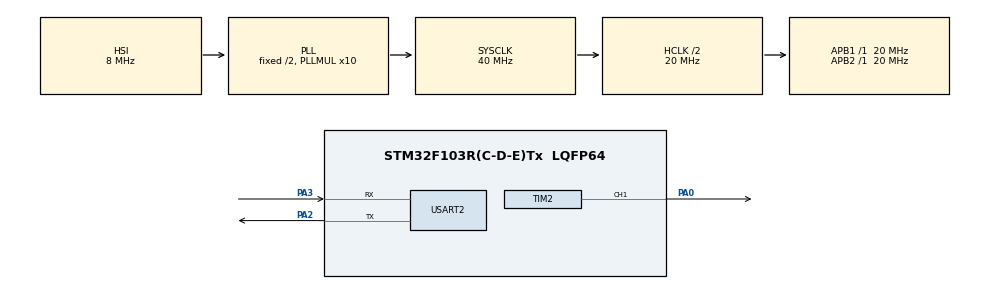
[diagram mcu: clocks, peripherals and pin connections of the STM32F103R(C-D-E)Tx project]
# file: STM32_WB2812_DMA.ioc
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Dma.Request0=TIM2_CH1
Dma.Request1=USART2_RX
Dma.Request2=USART2_TX
Dma.TIM2_CH1.0.Direction=DMA_MEMORY_TO_PERIPH
Dma.TIM2_CH1.0.Instance=DMA1_Channel5
Dma.TIM2_CH1.0.MemDataAlignment=DMA_MDATAALIGN_BYTE
Dma.TIM2_CH1.0.MemInc=DMA_MINC_ENABLE
Dma.TIM2_CH1.0.Mode=DMA_NORMAL
Dma.TIM2_CH1.0.PeriphDataAlignment=DMA_PDATAALIGN_HALFWORD
Dma.TIM2_CH1.0.PeriphInc=DMA_PINC_DISABLE
Dma.TIM2_CH1.0.Priority=DMA_PRIORITY_HIGH
Dma.USART2_RX.1.Direction=DMA_PERIPH_TO_MEMORY
Dma.USART2_RX.1.Instance=DMA1_Channel6
Dma.USART2_RX.1.MemDataAlignment=DMA_MDATAALIGN_BYTE
Dma.USART2_RX.1.MemInc=DMA_MINC_ENABLE
Dma.USART2_RX.1.Mode=DMA_NORMAL
Dma.USART2_RX.1.PeriphDataAlignment=DMA_PDATAALIGN_BYTE
Dma.USART2_RX.1.PeriphInc=DMA_PINC_DISABLE
Dma.USART2_RX.1.Priority=DMA_PRIORITY_LOW
Dma.USART2_TX.2.Direction=DMA_MEMORY_TO_PERIPH
Dma.USART2_TX.2.Instance=DMA1_Channel7
Dma.USART2_TX.2.MemDataAlignment=DMA_MDATAALIGN_BYTE
Dma.USART2_TX.2.MemInc=DMA_MINC_ENABLE
Dma.USART2_TX.2.Mode=DMA_NORMAL
Dma.USART2_TX.2.PeriphDataAlignment=DMA_PDATAALIGN_BYTE
Dma.USART2_TX.2.PeriphInc=DMA_PINC_DISABLE
Dma.USART2_TX.2.Priority=DMA_PRIORITY_LOW
FREERTOS.Tasks01=Wb2812TranferTa,8,128,Wb2812TranferCallback,Default,NULL,Dynamic,NULL,NULL;UartReceiveTask,24,128,UartReceiveCallback,Default,NULL,Dynamic,NULL,NULL;UartSendTask,40,128,UartSendCallback,Default,NULL,Dynamic,NULL,NULL;UartHandleTask,16,128,UartHandleCallback,Default,NULL,Dynamic,NULL,NULL
Mcu.Family=STM32F1
Mcu.Name=STM32F103R(C-D-E)Tx
Mcu.Package=LQFP64
NVIC.DMA1_Channel5_IRQn=true\:5\:0\:false\:false\:true\:true\:false\:true\:true
NVIC.DMA1_Channel6_IRQn=true\:5\:0\:false\:false\:true\:true\:false\:true\:true
NVIC.DMA1_Channel7_IRQn=true\:5\:0\:false\:false\:true\:true\:false\:true\:true
NVIC.PriorityGroup=NVIC_PRIORITYGROUP_4
NVIC.TIM2_IRQn=true\:5\:0\:false\:false\:true\:true\:true\:true\:true
NVIC.USART2_IRQn=true\:5\:0\:false\:false\:true\:true\:true\:true\:true
PA0-WKUP.Signal=S_TIM2_CH1_ETR
PA13.Mode=Serial_Wire
PA13.Signal=SYS_JTMS-SWDIO
PA14.Mode=Serial_Wire
PA14.Signal=SYS_JTCK-SWCLK
PA2.Mode=Asynchronous
PA2.Signal=USART2_TX
PA3.Mode=Asynchronous
PA3.Signal=USART2_RX
PD0-OSC_IN.Mode=HSE-External-Oscillator
PD0-OSC_IN.Signal=RCC_OSC_IN
PD1-OSC_OUT.Mode=HSE-External-Oscillator
PD1-OSC_OUT.Signal=RCC_OSC_OUT
ProjectManager.HeapSize=0x200
ProjectManager.StackSize=0x400
ProjectManager.TargetToolchain=STM32CubeIDE
RCC.AHBCLKDivider=RCC_SYSCLK_DIV2
RCC.AHBFreq_Value=20000000
RCC.APB1Freq_Value=20000000
RCC.APB1TimFreq_Value=20000000
RCC.APB2Freq_Value=20000000
RCC.APB2TimFreq_Value=20000000
RCC.HCLKFreq_Value=20000000
RCC.HSE_VALUE=12000000
RCC.PLLMUL=RCC_PLL_MUL10
RCC.SYSCLKFreq_VALUE=40000000
RCC.SYSCLKSource=RCC_SYSCLKSOURCE_PLLCLK
RCC.USBFreq_Value=26666666.666666668
RCC.USBPrescaler=RCC_USBCLKSOURCE_PLL_DIV1_5
SH.S_TIM2_CH1_ETR.0=TIM2_CH1,PWM Generation1 CH1
TIM2.AutoReloadPreload=TIM_AUTORELOAD_PRELOAD_ENABLE
TIM2.Channel-PWM\ Generation1\ CH1=TIM_CHANNEL_1
TIM2.Period=12
TIM2.Prescaler=1
TIM2.Pulse-PWM\ Generation1\ CH1=0
USART2.VirtualMode=VM_ASYNC
VP_FREERTOS_VS_CMSIS_V2.Mode=CMSIS_V2
VP_TIM2_VS_ClockSourceINT.Mode=Internal
board=custom

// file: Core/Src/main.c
/* USER CODE BEGIN Header */
/**
 ******************************************************************************
 * @file           : main.c
 * @brief          : Main program body
 ******************************************************************************
 * @attention
 *
 * Copyright (c) 2026 STMicroelectronics.
 * All rights reserved.
 *
 * This software is licensed under terms that can be found in the LICENSE file
 * in the root directory of this software component.
 * If no LICENSE file comes with this software, it is provided AS-IS.
 *
 ******************************************************************************
 */
/* USER CODE END Header */
#include "main.h"
#include "cmsis_os.h"

/* USER CODE BEGIN Includes */
#include "WB2812.h"
#include "UartCustom.h"
#include "message.h"
/* USER CODE END Includes */

/* USER CODE BEGIN PTD */
typedef enum{
	UART_CODE_NOT_USED														= 0x11,
	UART_CODE_HEADER														= 0x89,
	UART_CODE_GET_PIXEL_LED													= 0x100,
	UART_CODE_SET_COLOR														= 0x999,
	UART_CODE_SET_COLOR_OK													= 0x1001
} opCodeUartEnum;

/* USER CODE END PTD */

/* USER CODE BEGIN PD */
#define WB2812_CODE_0_DUTY														4
#define WB2812_CODE_1_DUTY														8
#define WB2812_WIDTH															2
#define WB2812_HEIGTH															1
#define WB2812_TIME_DUTY_CODE_0													4
#define WB2812_TIME_DUTY_CODE_1													7
#define WB2812_RED_BALANCE														1
#define WB2812_GREEN_BALANCE													1
#define WB2812_BLUE_BALANCE														1
#define WB2812_GAMMA															2.4
#define MSG_LENGTH_MAX															128
#define QUEUE_SIZE_MAX															3
/* USER CODE END PD */

TIM_HandleTypeDef htim2;
DMA_HandleTypeDef hdma_tim2_ch1;

UART_HandleTypeDef huart2;
DMA_HandleTypeDef hdma_usart2_rx;
DMA_HandleTypeDef hdma_usart2_tx;

/* Definitions for Wb2812TranferTa */
osThreadId_t Wb2812TranferTaHandle;
const osThreadAttr_t Wb2812TranferTa_attributes = {
  .name = "Wb2812TranferTa",
  .stack_size = 128 * 4,
  .priority = (osPriority_t) osPriorityLow,
};
/* Definitions for UartReceiveTask */
osThreadId_t UartReceiveTaskHandle;
const osThreadAttr_t UartReceiveTask_attributes = {
  .name = "UartReceiveTask",
  .stack_size = 128 * 4,
  .priority = (osPriority_t) osPriorityNormal,
};
/* Definitions for UartSendTask */
osThreadId_t UartSendTaskHandle;
const osThreadAttr_t UartSendTask_attributes = {
  .name = "UartSendTask",
  .stack_size = 128 * 4,
  .priority = (osPriority_t) osPriorityHigh,
};
/* Definitions for UartHandleTask */
osThreadId_t UartHandleTaskHandle;
const osThreadAttr_t UartHandleTask_attributes = {
  .name = "UartHandleTask",
  .stack_size = 128 * 4,
  .priority = (osPriority_t) osPriorityBelowNormal,
};
/* USER CODE BEGIN PV */
MsgQueue uartMsgQueueReceive;
MsgQueue uartMsgQueueSend;
WB2812Image_t image;
TaskHandle_t wb2812Task;
TaskHandle_t wb2812requestTask;
/* USER CODE END PV */

void SystemClock_Config(void);
static void MX_GPIO_Init(void);
static void MX_DMA_Init(void);
static void MX_TIM2_Init(void);
static void MX_USART2_UART_Init(void);
void Wb2812TranferCallback(void *argument);
void UartReceiveCallback(void *argument);
void UartSendCallback(void *argument);
void UartHandleCallback(void *argument);

/* USER CODE BEGIN PFP */
static void WB2812Config(void);
void HandleMsgUart(uint8_t *content);
void CopyWb2812ImageByte(uint8_t *content, uint32_t size, Msg *msg);
/* USER CODE END PFP */

int main(void)
{

  /* MCU Configuration--------------------------------------------------------*/

  /* Reset of all peripherals, Initializes the Flash interface and the Systick. */
  HAL_Init();

  /* Configure the system clock */
  SystemClock_Config();

  /* Initialize all configured peripherals */
  MX_GPIO_Init();
  MX_DMA_Init();
  MX_TIM2_Init();
  MX_USART2_UART_Init();
  /* USER CODE BEGIN 2 */
	UartCustomInit(&huart2, MSG_LENGTH_MAX);
	WB2812Config();
	WB2812ImageInit(&image);
  /* USER CODE END 2 */

  /* Init scheduler */
  osKernelInitialize();

  /* USER CODE BEGIN RTOS_QUEUES */
	/* add queues, ... */
	MsgQueueInit(&uartMsgQueueReceive, QUEUE_SIZE_MAX, MSG_LENGTH_MAX);
	MsgQueueInit(&uartMsgQueueSend, QUEUE_SIZE_MAX, MSG_LENGTH_MAX);
  /* USER CODE END RTOS_QUEUES */

  /* Create the thread(s) */
  /* creation of Wb2812TranferTa */
  Wb2812TranferTaHandle = osThreadNew(Wb2812TranferCallback, NULL, &Wb2812TranferTa_attributes);

  /* creation of UartReceiveTask */
  UartReceiveTaskHandle = osThreadNew(UartReceiveCallback, NULL, &UartReceiveTask_attributes);

  /* creation of UartSendTask */
  UartSendTaskHandle = osThreadNew(UartSendCallback, NULL, &UartSendTask_attributes);

  /* creation of UartHandleTask */
  UartHandleTaskHandle = osThreadNew(UartHandleCallback, NULL, &UartHandleTask_attributes);

  /* Start scheduler */
  osKernelStart();

  /* We should never get here as control is now taken by the scheduler */

  /* Infinite loop */
	while (1) {

	}
}

void SystemClock_Config(void)
{
  RCC_OscInitTypeDef RCC_OscInitStruct = {0};
  RCC_ClkInitTypeDef RCC_ClkInitStruct = {0};

  /** Initializes the RCC Oscillators according to the specified parameters
  * in the RCC_OscInitTypeDef structure.
  */
  RCC_OscInitStruct.OscillatorType = RCC_OSCILLATORTYPE_HSI;
  RCC_OscInitStruct.HSIState = RCC_HSI_ON;
  RCC_OscInitStruct.HSICalibrationValue = RCC_HSICALIBRATION_DEFAULT;
  RCC_OscInitStruct.PLL.PLLState = RCC_PLL_ON;
  RCC_OscInitStruct.PLL.PLLSource = RCC_PLLSOURCE_HSI_DIV2;
  RCC_OscInitStruct.PLL.PLLMUL = RCC_PLL_MUL10;
  if (HAL_RCC_OscConfig(&RCC_OscInitStruct) != HAL_OK)
  {
    Error_Handler();
  }

  /** Initializes the CPU, AHB and APB buses clocks
  */
  RCC_ClkInitStruct.ClockType = RCC_CLOCKTYPE_HCLK|RCC_CLOCKTYPE_SYSCLK
                              |RCC_CLOCKTYPE_PCLK1|RCC_CLOCKTYPE_PCLK2;
  RCC_ClkInitStruct.SYSCLKSource = RCC_SYSCLKSOURCE_PLLCLK;
  RCC_ClkInitStruct.AHBCLKDivider = RCC_SYSCLK_DIV2;
  RCC_ClkInitStruct.APB1CLKDivider = RCC_HCLK_DIV1;
  RCC_ClkInitStruct.APB2CLKDivider = RCC_HCLK_DIV1;

  if (HAL_RCC_ClockConfig(&RCC_ClkInitStruct, FLASH_LATENCY_1) != HAL_OK)
  {
    Error_Handler();
  }
}

static void MX_TIM2_Init(void)
{

  TIM_ClockConfigTypeDef sClockSourceConfig = {0};
  TIM_MasterConfigTypeDef sMasterConfig = {0};
  TIM_OC_InitTypeDef sConfigOC = {0};

  htim2.Instance = TIM2;
  htim2.Init.Prescaler = 1;
  htim2.Init.CounterMode = TIM_COUNTERMODE_UP;
  htim2.Init.Period = 12;
  htim2.Init.ClockDivision = TIM_CLOCKDIVISION_DIV1;
  htim2.Init.AutoReloadPreload = TIM_AUTORELOAD_PRELOAD_ENABLE;
  if (HAL_TIM_Base_Init(&htim2) != HAL_OK)
  {
    Error_Handler();
  }
  sClockSourceConfig.ClockSource = TIM_CLOCKSOURCE_INTERNAL;
  if (HAL_TIM_ConfigClockSource(&htim2, &sClockSourceConfig) != HAL_OK)
  {
    Error_Handler();
  }
  if (HAL_TIM_PWM_Init(&htim2) != HAL_OK)
  {
    Error_Handler();
  }
  sMasterConfig.MasterOutputTrigger = TIM_TRGO_RESET;
  sMasterConfig.MasterSlaveMode = TIM_MASTERSLAVEMODE_DISABLE;
  if (HAL_TIMEx_MasterConfigSynchronization(&htim2, &sMasterConfig) != HAL_OK)
  {
    Error_Handler();
  }
  sConfigOC.OCMode = TIM_OCMODE_PWM1;
  sConfigOC.Pulse = 0;
  sConfigOC.OCPolarity = TIM_OCPOLARITY_HIGH;
  sConfigOC.OCFastMode = TIM_OCFAST_DISABLE;
  if (HAL_TIM_PWM_ConfigChannel(&htim2, &sConfigOC, TIM_CHANNEL_1) != HAL_OK)
  {
    Error_Handler();
  }
  HAL_TIM_MspPostInit(&htim2);

}

static void MX_USART2_UART_Init(void)
{

  huart2.Instance = USART2;
  huart2.Init.BaudRate = 115200;
  huart2.Init.WordLength = UART_WORDLENGTH_8B;
  huart2.Init.StopBits = UART_STOPBITS_1;
  huart2.Init.Parity = UART_PARITY_NONE;
  huart2.Init.Mode = UART_MODE_TX_RX;
  huart2.Init.HwFlowCtl = UART_HWCONTROL_NONE;
  huart2.Init.OverSampling = UART_OVERSAMPLING_16;
  if (HAL_UART_Init(&huart2) != HAL_OK)
  {
    Error_Handler();
  }

}

static void MX_DMA_Init(void)
{

  /* DMA controller clock enable */
  __HAL_RCC_DMA1_CLK_ENABLE();

  /* DMA interrupt init */
  /* DMA1_Channel5_IRQn interrupt configuration */
  HAL_NVIC_SetPriority(DMA1_Channel5_IRQn, 5, 0);
  HAL_NVIC_EnableIRQ(DMA1_Channel5_IRQn);
  /* DMA1_Channel6_IRQn interrupt configuration */
  HAL_NVIC_SetPriority(DMA1_Channel6_IRQn, 5, 0);
  HAL_NVIC_EnableIRQ(DMA1_Channel6_IRQn);
  /* DMA1_Channel7_IRQn interrupt configuration */
  HAL_NVIC_SetPriority(DMA1_Channel7_IRQn, 5, 0);
  HAL_NVIC_EnableIRQ(DMA1_Channel7_IRQn);

}

static void MX_GPIO_Init(void)
{

  /* GPIO Ports Clock Enable */
  __HAL_RCC_GPIOD_CLK_ENABLE();
  __HAL_RCC_GPIOA_CLK_ENABLE();

}

/* USER CODE BEGIN 4 */
static void WB2812Config(void) {
	WB2812_SetSize(WB2812_WIDTH, WB2812_HEIGTH);
	WB2812_SetLutGamma(WB2812_GREEN_BALANCE, WB2812_RED_BALANCE,
	WB2812_BLUE_BALANCE, WB2812_GAMMA);
	WB2812_SetTimAndChannel(&htim2, TIM_CHANNEL_1);
	WB2812_SetDutyCode(WB2812_TIME_DUTY_CODE_0, WB2812_TIME_DUTY_CODE_1);
}

void CopyWb2812ImageByte(uint8_t *content, uint32_t size, Msg *msg){
	memcpy(image.imageByte, content, size);
	xTaskNotifyGive(wb2812Task);
	ulTaskNotifyTake(pdTRUE, portMAX_DELAY);
	AddUlongToMessage(msg->content + HEADER_MESSAGE, UART_CODE_SET_COLOR_OK, UART_CODE_NOT_USED);
	msg->length += (ULONG_MESSAGE_TYPE + CONTENT_FIELD_MESSAGE_START);
}

void HandleMsgUart(uint8_t *content){
	Msg *msg;
	HeaderFieldMessage info;
	GetMsgFromMsgFreeQueue(&uartMsgQueueSend, &msg, portMAX_DELAY);
	msg->length = 0;
	GetFieldInMessage(content, &info);
	switch(info.code){
		case UART_CODE_GET_PIXEL_LED:
			AddUlongToMessage(msg->content + HEADER_MESSAGE, UART_CODE_GET_PIXEL_LED, WB2812_WIDTH * WB2812_HEIGTH);
			msg->length += (ULONG_MESSAGE_TYPE + CONTENT_FIELD_MESSAGE_START);
			break;
		case UART_CODE_SET_COLOR:
			CopyWb2812ImageByte(content + CONTENT_FIELD_MESSAGE_START, WB2812_WIDTH * WB2812_HEIGTH * WB2812_COLOR_BYTE, msg);
			break;
	}
	msg->length += HEADER_MESSAGE;
	AddUlongToMessage(msg->content, UART_CODE_HEADER, msg->length);
	PushMsgToMsgReadyQueue(&uartMsgQueueSend, msg, portMAX_DELAY);
}
/* USER CODE END 4 */

void Wb2812TranferCallback(void *argument)
{
  /* USER CODE BEGIN 5 */
	/* Infinite loop */
	WB2812Duty_t duty;
	WB2812DutyInit(&duty);
	wb2812Task = xTaskGetCurrentTaskHandle();
	for (;;) {
		ulTaskNotifyTake(pdTRUE, portMAX_DELAY);
		WB2812_ConvertDutyFormImage(&image, &duty);
		WB2812_Show(&duty);
		xTaskNotifyGive(wb2812requestTask);
	}
  /* USER CODE END 5 */
}

void UartReceiveCallback(void *argument)
{
  /* USER CODE BEGIN UartReceiveCallback */
	Msg *msg;
	TaskHandle_t task = xTaskGetCurrentTaskHandle();
	/* Infinite loop */
	for (;;) {
		GetMsgFromMsgFreeQueue(&uartMsgQueueReceive, &msg, portMAX_DELAY);
		UartStartRxTranfer(task, msg);
		PushMsgToMsgReadyQueue(&uartMsgQueueReceive, msg, portMAX_DELAY);
	}
  /* USER CODE END UartReceiveCallback */
}

void UartSendCallback(void *argument)
{
  /* USER CODE BEGIN UartSendCallback */
	TaskHandle_t task = xTaskGetCurrentTaskHandle();
	Msg *msg;
	/* Infinite loop */
	for (;;) {
		GetMsgFromMsgReadyQueue(&uartMsgQueueSend, &msg, portMAX_DELAY);
		UartStartTxTransfer(task, msg);
		PushMsgToMsgFreeQueue(&uartMsgQueueSend, msg, portMAX_DELAY);
	}
  /* USER CODE END UartSendCallback */
}

void UartHandleCallback(void *argument)
{
  /* USER CODE BEGIN UartHandleCallback */
	Msg *msg;
	wb2812requestTask = xTaskGetCurrentTaskHandle();
	HeaderFieldMessage info;
	/* Infinite loop */
	for (;;) {
		GetMsgFromMsgReadyQueue(&uartMsgQueueReceive, &msg, portMAX_DELAY);
		GetFieldInMessage(msg->content, &info);
		switch(info.code){
			case UART_CODE_HEADER:
				HandleMsgUart(msg->content + HEADER_MESSAGE);
				break;
			default:
				break;
		}
		PushMsgToMsgFreeQueue(&uartMsgQueueReceive, msg, portMAX_DELAY);
	}
  /* USER CODE END UartHandleCallback */
}

void Error_Handler(void)
{
	__disable_irq();
	while (1) {
	}
}
